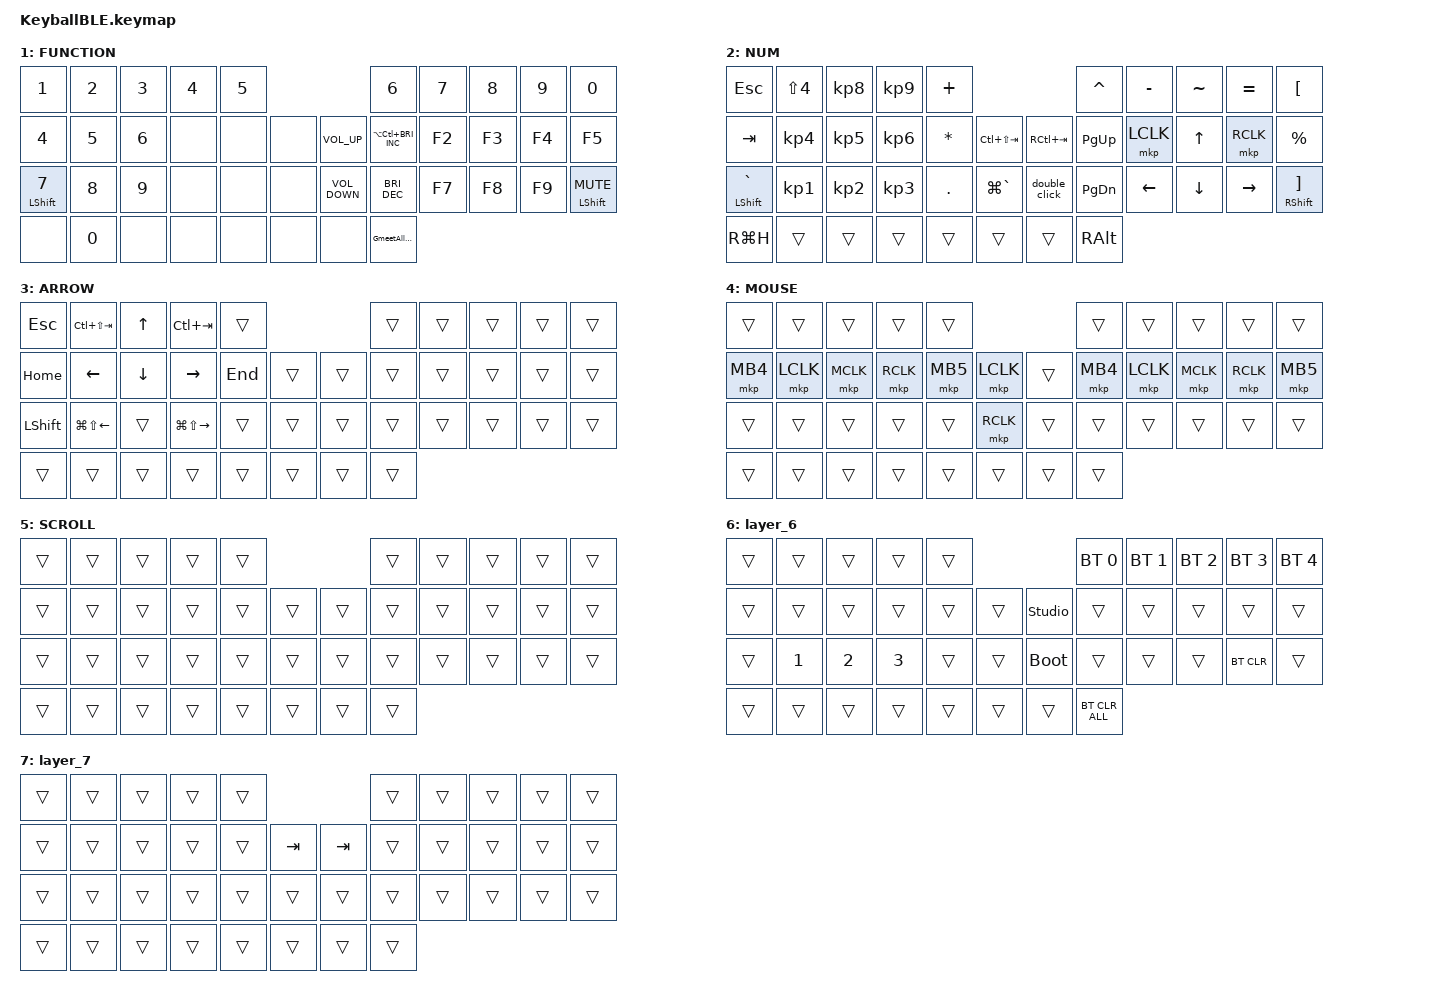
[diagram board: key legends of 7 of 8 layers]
#include <behaviors.dtsi>
#include <dt-bindings/zmk/bt.h>
#include <dt-bindings/zmk/keys.h>
#include <dt-bindings/zmk/pointing.h>

#define MOUSE 4
#define SCROLL 5
#define NUM 6
#define APPSW 7

&mt {
    flavor = "balanced";
    quick-tap-ms = <0>;
};

/ {
    combos {
        compatible = "zmk,combos";

        double_quotation {
            bindings = <&kp DOUBLE_QUOTES>;
            key-positions = <20 21 23>;
        };

        bullets {
            bindings = <&kp LS(LG(N8))>;
            key-positions = <10 21>;
        };

        bullet2 {
            bindings = <&kp LS(LG(N7))>;
            key-positions = <0 9>;
        };
    };

    macros {
        to_layer_0: to_layer_0 {
            compatible = "zmk,behavior-macro-one-param";
            #binding-cells = <1>;
            bindings = <&to 0 &macro_param_1to1 &kp MACRO_PLACEHOLDER>;
            label = "TO_LAYER_0";
        };

        GmeetAllmute: GmeetAllmute {
            compatible = "zmk,behavior-macro";
            #binding-cells = <0>;
            bindings =
                <&macro_press>,
                <&kp LGUI>,
                <&macro_tap>,
                <&kp D>,
                <&macro_release>,
                <&kp LGUI>,
                <&macro_wait_time 50>,
                <&macro_press>,
                <&kp LGUI>,
                <&macro_tap>,
                <&kp E>,
                <&macro_release>,
                <&kp LGUI>;
        };

        double_click: double_click {
            compatible = "zmk,behavior-macro";
            #binding-cells = <0>;
            bindings = <&mkp LCLK &mkp LCLK>;
            label = "DOUBLE_CLICK";
            wait-ms = <500>;
            tap-ms = <100>;
        };

        app_switch: app_switch {
            compatible = "zmk,behavior-macro";
            #binding-cells = <0>;
            label = "APP_SWITCH";
            wait-ms = <10>;
            tap-ms = <20>;
            bindings
                = <&macro_press &kp LGUI>
                , <&macro_tap &kp TAB>
                , <&macro_press &mo APPSW>
                , <&macro_pause_for_release>
                , <&macro_release &mo APPSW>
                , <&macro_release &kp LGUI>
                ;
        };

        app_switch_rev: app_switch_rev {
            compatible = "zmk,behavior-macro";
            #binding-cells = <0>;
            label = "APP_SWITCH_REV";
            wait-ms = <10>;
            tap-ms = <20>;
            bindings
                = <&macro_press &kp LGUI &kp LSHFT>
                , <&macro_tap &kp TAB>
                , <&macro_press &mo APPSW>
                , <&macro_pause_for_release>
                , <&macro_release &mo APPSW>
                , <&macro_release &kp LGUI &kp LSHFT>
                ;
        };
    };

    behaviors {
        lt_to_layer_0: lt_to_layer_0 {
            compatible = "zmk,behavior-hold-tap";
            label = "LAYER_TAP_TO_0";
            bindings = <&mo>, <&to_layer_0>;

            #binding-cells = <2>;
            tapping-term-ms = <200>;
        };
    };

    keymap {
        compatible = "zmk,keymap";

        default_layer {
            bindings = <
&kp Q               &kp W             &kp E         &kp R                   &kp T                                                                                &kp Y                   &kp U  &lt 5 I    &kp O    &kp P
&kp A               &kp S             &kp D         &kp F                   &kp G        &app_switch                                    &app_switch_rev          &kp H                   &kp J  &kp K      &kp L    &kp SEMICOLON
&mt LEFT_SHIFT Z    &kp X             &kp C         &kp V                   &kp B        &lt_to_layer_0 4 LC(LEFT_ARROW)                &kp RC(RIGHT)            &kp N                   &kp M  &kp COMMA  &kp DOT  &mt RSHFT SLASH
&mt LEFT_ALT GLOBE  &kp LEFT_CONTROL  &kp LEFT_GUI  &lt_to_layer_0 1 LANG5  &lt 2 SPACE  &lt_to_layer_0 6 LC(LS(RS(INT_MUHENKAN)))      &mt RIGHT_ALT BACKSPACE  &lt_to_layer_0 1 ENTER                             &kp BACKSLASH
            >;

            sensor-bindings = <&inc_dec_kp PG_UP PAGE_DOWN>;
        };

        FUNCTION {
            bindings = <
&kp NUMBER_1  &kp NUMBER_2  &kp NUMBER_3  &kp NUMBER_4  &kp N5                                &kp NUMBER_6                  &kp N7  &kp N8  &kp N9  &kp N0
&kp NUMBER_4  &kp N5        &kp NUMBER_6  &none         &none   &none      &kp C_VOLUME_UP    &kp LA(LC(C_BRIGHTNESS_INC))  &kp F2  &kp F3  &kp F4  &kp F5
&mt LSHFT N7  &kp N8        &kp N9        &none         &none   &none      &kp C_VOLUME_DOWN  &kp C_BRIGHTNESS_DEC          &kp F7  &kp F8  &kp F9  &mt LSHFT K_MUTE
&none         &kp NUMBER_0  &none         &none         &none   &none      &none              &GmeetAllmute
            >;
        };

        NUM {
            bindings = <
&kp ESC               &kp LS(NUMBER_4)  &kp KP_NUMBER_8  &kp KP_NUMBER_9  &kp PLUS                                          &kp CARET      &kp MINUS       &kp TILDE       &kp EQUAL  &kp LEFT_BRACKET
&kp TAB               &kp KP_NUMBER_4   &kp KP_NUMBER_5  &kp KP_NUMBER_6  &kp ASTERISK  &kp LC(LS(TAB))      &kp RC(TAB)    &kp PAGE_UP    &mkp LCLK       &kp UP_ARROW    &mkp RCLK  &kp PERCENT
&mt LEFT_SHIFT GRAVE  &kp KP_NUMBER_1   &kp KP_NUMBER_2  &kp KP_NUMBER_3  &kp PERIOD    &kp LG(GRAVE)        &double_click  &kp PAGE_DOWN  &kp LEFT_ARROW  &kp DOWN_ARROW  &kp RIGHT  &mt RSHFT RIGHT_BRACKET
&kp RG(H)             &trans            &trans           &trans           &trans        &trans               &trans         &kp RIGHT_ALT
            >;
        };

        ARROW {
            bindings = <
&kp ESCAPE      &kp LC(LS(TAB))         &kp UP_ARROW    &kp LC(TAB)              &trans                       &trans  &trans  &trans  &trans  &trans
&kp HOME        &kp LEFT_ARROW          &kp DOWN_ARROW  &kp RIGHT_ARROW          &kp END  &trans      &trans  &trans  &trans  &trans  &trans  &trans
&kp LEFT_SHIFT  &kp LG(LS(LEFT_ARROW))  &trans          &kp LG(LS(RIGHT_ARROW))  &trans   &trans      &trans  &trans  &trans  &trans  &trans  &trans
&trans          &trans                  &trans          &trans                   &trans   &trans      &trans  &trans
            >;

            sensor-bindings = <&inc_dec_kp LC(PAGE_UP) LC(PAGE_DOWN)>;
        };

        MOUSE {
            bindings = <
&trans    &trans     &trans     &trans     &trans                           &trans    &trans     &trans     &trans     &trans
&mkp MB4  &mkp LCLK  &mkp MCLK  &mkp RCLK  &mkp MB5  &mkp LCLK      &trans  &mkp MB4  &mkp LCLK  &mkp MCLK  &mkp RCLK  &mkp MB5
&trans    &trans     &trans     &trans     &trans    &mkp RCLK      &trans  &trans    &trans     &trans     &trans     &trans
&trans    &trans     &trans     &trans     &trans    &trans         &trans  &trans
            >;
        };

        SCROLL {
            bindings = <
&trans  &trans  &trans  &trans  &trans                      &trans  &trans  &trans  &trans  &trans
&trans  &trans  &trans  &trans  &trans  &trans      &trans  &trans  &trans  &trans  &trans  &trans
&trans  &trans  &trans  &trans  &trans  &trans      &trans  &trans  &trans  &trans  &trans  &trans
&trans  &trans  &trans  &trans  &trans  &trans      &trans  &trans
            >;
        };

        layer_6 {
            bindings = <
&trans  &trans        &trans        &trans        &trans                              &bt BT_SEL 0    &bt BT_SEL 1  &bt BT_SEL 2  &bt BT_SEL 3  &bt BT_SEL 4
&trans  &trans        &trans        &trans        &trans  &trans      &studio_unlock  &trans          &trans        &trans        &trans        &trans
&trans  &kp NUMBER_1  &kp NUMBER_2  &kp NUMBER_3  &trans  &trans      &bootloader     &trans          &trans        &trans        &bt BT_CLR    &trans
&trans  &trans        &trans        &trans        &trans  &trans      &trans          &bt BT_CLR_ALL
            >;
        };

        layer_7 {
            bindings = <
&trans  &trans  &trans  &trans  &trans                        &trans   &trans  &trans  &trans  &trans
&trans  &trans  &trans  &trans  &trans  &kp TAB      &kp TAB  &trans   &trans  &trans  &trans  &trans
&trans  &trans  &trans  &trans  &trans  &trans       &trans   &trans   &trans  &trans  &trans  &trans
&trans  &trans  &trans  &trans  &trans  &trans       &trans   &trans
            >;
        };
    };
};
